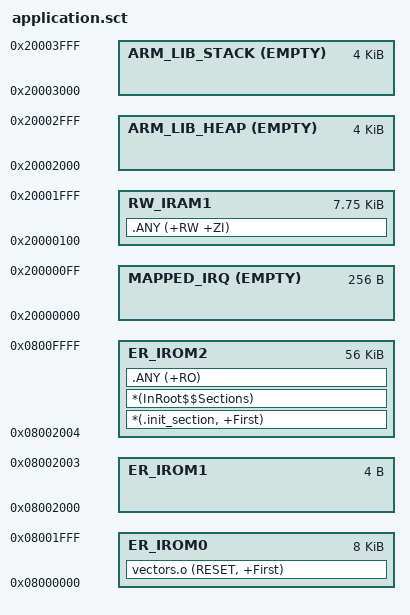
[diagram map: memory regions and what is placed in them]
; *************************************************************
; *** Scatter-Loading Description File generated by uVision ***
; *************************************************************

LR_IROM0 0x08000000 0x2000
{
	ER_IROM0 0x08000000 0x2000
	{
		vectors.o (RESET, +First)
	}
}


; load region size_region
; Sector 0-1 (0x0800 0000 - 0x0800 1FFF) (8 kbytes) = bootloader
; Sector 2-15 (0x0800 2000 - 0x0800 FFFF) (56 kbytes) = firmware
; Sector 16-29 (0x0800 3000 - 0x0801 DFFF) (56 kbytes) = image
; Sector 30-31 (0x0801 E000 - 0x0801 FFFF) (8 kbytes) = reserved
LR_IROM1 0x08002000 0xE000
{
	; load address = execution address (size, crc)
	ER_IROM1 0x08002000 FILL 0x00000000 4
	{
	}
	
	; load address = execution address
	ER_IROM2 0x08002004 0xE000 - 4
	{
		*(.init_section, +First)
		*(InRoot$$Sections)
		.ANY (+RO)
	}
	
	; RAM 
	; mapped IRQ (256)
	MAPPED_IRQ 0x20000000 EMPTY 0x0100
	{
	}
	
	; RW data (8 kbytes - 256 bytes)
	RW_IRAM1 0x20000100 0x1F00
	{
		.ANY (+RW +ZI)
	}
	
	; HEAP space (4 kbytes)
	ARM_LIB_HEAP 0x20002000 EMPTY 0x1000
	{
	}
	
	; STACK space (4 kbytes)
	ARM_LIB_STACK 0x20004000 EMPTY -0x1000
	{
	}
}
